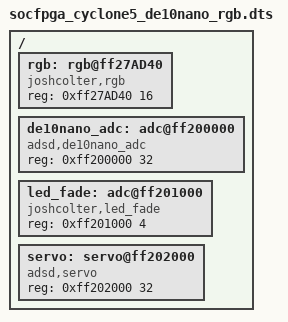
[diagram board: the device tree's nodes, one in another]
#include "socfpga_cyclone5_de10nano.dtsi"
/{
rgb: rgb@ff27AD40 {
    compatible = "joshcolter,rgb";
    reg = <0xff27AD40 16>;
};


de10nano_adc: adc@ff200000 {
    compatible = "adsd,de10nano_adc";
    reg = <0xff200000 32>;
};

led_fade: adc@ff201000 {
    compatible = "joshcolter,led_fade";
    reg = <0xff201000 4>;
};

servo: servo@ff202000 {
    compatible = "adsd,servo";
    reg = <0xff202000 32>;
};
};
